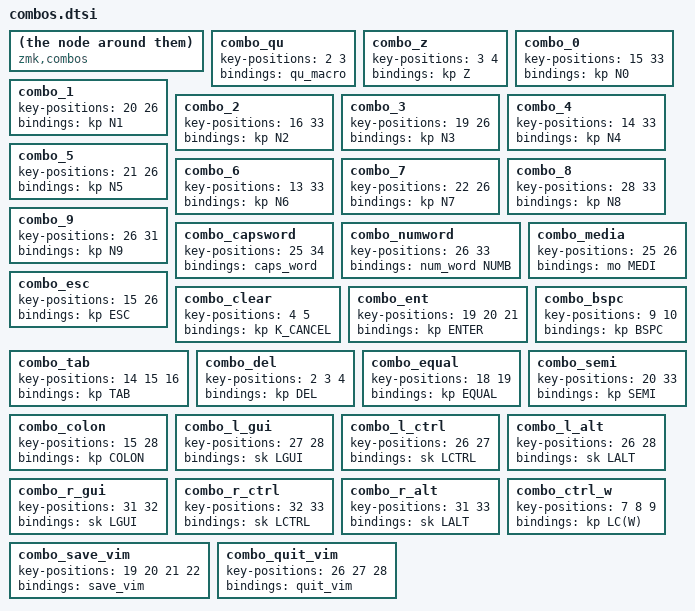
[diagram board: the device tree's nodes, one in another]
/*                KEY POSITIONS
  ╭────────────────────────╮ ╭────────────────────────╮
  │  X   1   2   3   4   5 │ │  6   7   8   9  10   X │
  │  X  13  14  15  16  17 │ │ 18  19  20  21  22   X │
  │  X  25  26  27  28  29 │ │ 30  31  32  33  34   X │
  ╰───────────╮ 36  37  38 │ │ 39  40  41 ╭───────────╯
              ╰────────────╯ ╰────────────╯       */

compatible = "zmk,combos";

// Letters
combo_qu {
    key-positions = <2 3>;
    bindings = <&qu_macro>;
};
combo_z {
    key-positions = <3 4>;
    bindings = <&kp Z>;
};
// Numbers
combo_0 {
    key-positions = <15 33>;
    bindings = <&kp N0>;
};
combo_1 {
    key-positions = <20 26>;
    bindings = <&kp N1>;
};
combo_2 {
    key-positions = <16 33>;
    bindings = <&kp N2>;
};
combo_3 {
    key-positions = <19 26>;
    bindings = <&kp N3>;
};
combo_4 {
    key-positions = <14 33>;
    bindings = <&kp N4>;
};
combo_5 {
    key-positions = <21 26>;
    bindings = <&kp N5>;
};
combo_6 {
    key-positions = <13 33>;
    bindings = <&kp N6>;
};
combo_7 {
    key-positions = <22 26>;
    bindings = <&kp N7>;
};
combo_8 {
    key-positions = <28 33>;
    bindings = <&kp N8>;
};
combo_9 {
    key-positions = <26 31>;
    bindings = <&kp N9>;
};
// Layers
combo_capsword {
    key-positions = <25 34>;
    bindings = <&caps_word>;
};
combo_numword {
    key-positions = <26 33>;
    bindings = <&num_word NUMB>;
};
combo_media {
    key-positions = <25 26>;
    bindings = <&mo MEDI>;
};
// Controls
combo_esc {
    key-positions = <15 26>;
    bindings = <&kp ESC>;
};
combo_clear {
    key-positions = <4 5>;
    bindings = <&kp K_CANCEL>;
};
combo_ent {
    key-positions = <19 20 21>;
    bindings = <&kp ENTER>;
};
combo_tab {
    key-positions = <14 15 16>;
    bindings = <&kp TAB>;
};
combo_bspc {
    key-positions = <9 10>;
    bindings = <&kp BSPC>;
};
combo_del {
    key-positions = <2 3 4>;
    bindings = <&kp DEL>;
};
// Symbols
combo_equal {
    key-positions = <18 19>;
    bindings = <&kp EQUAL>;
};
combo_semi {
    key-positions = <20 33>;
    bindings = <&kp SEMI>;
};
combo_colon {
    key-positions = <15 28>;
    bindings = <&kp COLON>;
};
// Mods
combo_l_gui {
    key-positions = <27 28>;
    bindings = <&sk LGUI>;
};
combo_l_ctrl {
    key-positions = <26 27>;
    bindings = <&sk LCTRL>;
};
combo_l_alt {
    key-positions = <26 28>;
    bindings = <&sk LALT>;
};
combo_r_gui {
    key-positions = <31 32>;
    bindings = <&sk LGUI>;
};
combo_r_ctrl {
    key-positions = <32 33>;
    bindings = <&sk LCTRL>;
};
combo_r_alt {
    key-positions = <31 33>;
    bindings = <&sk LALT>;
};
// Vim
combo_ctrl_w {
    key-positions = <7 8 9>;
    bindings = <&kp LC(W)>;
};
combo_save_vim {
    key-positions = <19 20 21 22>;
    bindings = <&save_vim>;
};
combo_quit_vim {
    key-positions = <26 27 28>;
    bindings = <&quit_vim>;
};
